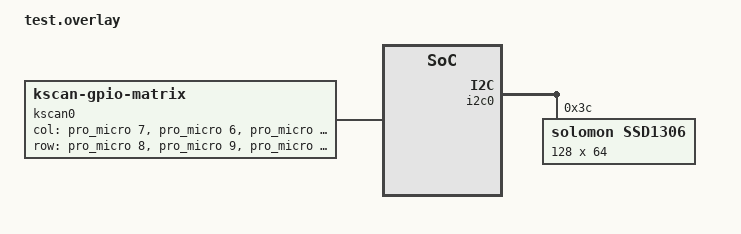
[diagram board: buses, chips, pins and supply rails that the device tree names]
/ {
    chosen {
        zmk,kscan = &kscan0;
    };

    kscan0: kscan_0 {
        compatible = "zmk,kscan-gpio-matrix";
        diode-direction = "col2row";
        wakeup-source;

        col-gpios
            = <&pro_micro 7 GPIO_ACTIVE_HIGH>
            , <&pro_micro 6 GPIO_ACTIVE_HIGH>
            , <&pro_micro 5 GPIO_ACTIVE_HIGH>
	        , <&pro_micro 4 GPIO_ACTIVE_HIGH>
            , <&pro_micro 1 GPIO_ACTIVE_HIGH>
            , <&pro_micro 0 GPIO_ACTIVE_HIGH>
            , <&pro_micro 21 GPIO_ACTIVE_HIGH>
            , <&pro_micro 20 GPIO_ACTIVE_HIGH>
            , <&pro_micro 19 GPIO_ACTIVE_HIGH>
            , <&pro_micro 18 GPIO_ACTIVE_HIGH>
            , <&pro_micro 15 GPIO_ACTIVE_HIGH>
            , <&pro_micro 14 GPIO_ACTIVE_HIGH>
            ;

        row-gpios
            = <&pro_micro 8 (GPIO_ACTIVE_HIGH | GPIO_PULL_DOWN)>
            , <&pro_micro 9 (GPIO_ACTIVE_HIGH | GPIO_PULL_DOWN)>
            , <&pro_micro 16 (GPIO_ACTIVE_HIGH | GPIO_PULL_DOWN)>
            ;
    };
};

&i2c0 {
    status = "okay";

    ssd1306: ssd1306@3c {
        compatible = "solomon,ssd1306";
        reg = <0x3c>;
        label = "SSD1306";
        width = <128>;
        height = <64>;
    };
};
